VERSION ""

NS_ :

BS_:

BU_:

BO_ 257 state: 1 Vector__XXX
 SG_ system_state : 0|8@1+ (1,0) [0|255] "" Vector__XXX

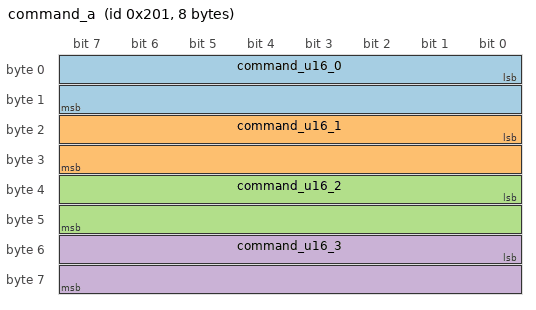
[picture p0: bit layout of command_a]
BO_ 513 command_a: 8 Vector__XXX
 SG_ command_u16_0 : 0|16@1+ (1,0) [0|65535] "unit" Vector__XXX
 SG_ command_u16_1 : 16|16@1+ (1,0) [0|65535] "unit" Vector__XXX
 SG_ command_u16_2 : 32|16@1+ (1,0) [0|65535] "unit" Vector__XXX
 SG_ command_u16_3 : 48|16@1+ (1,0) [0|65535] "unit" Vector__XXX

CM_ BO_ 257 "State machine info";
BA_DEF_  "BusType" STRING ;
BA_DEF_DEF_  "BusType" "CAN";
